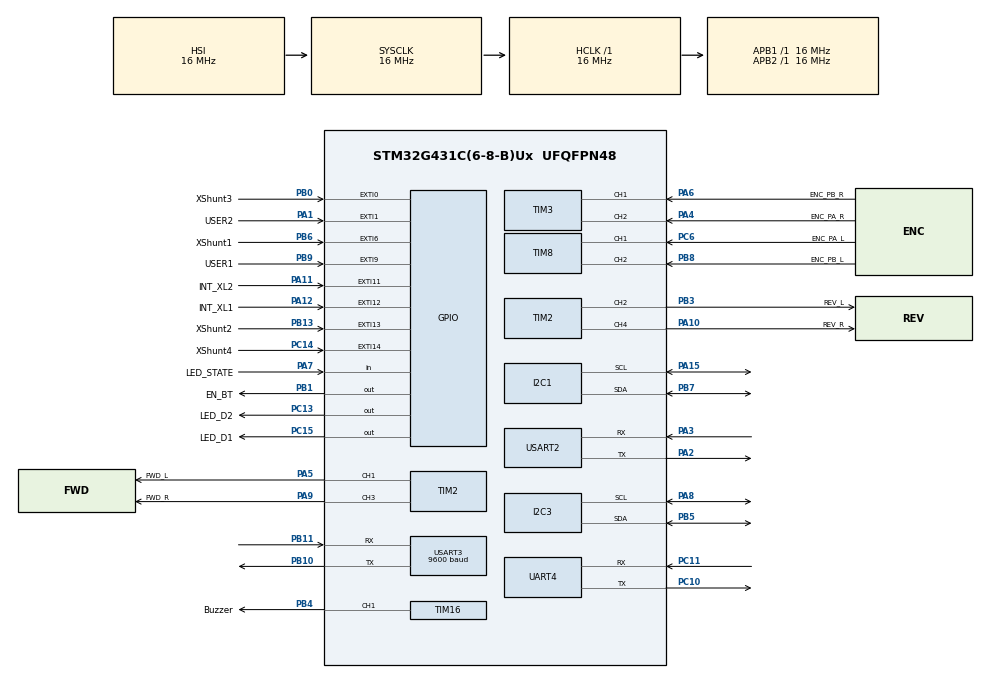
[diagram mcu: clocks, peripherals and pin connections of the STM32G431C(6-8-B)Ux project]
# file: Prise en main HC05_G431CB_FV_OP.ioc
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Dma.Request0=USART3_TX
Dma.USART3_TX.0.Direction=DMA_MEMORY_TO_PERIPH
Dma.USART3_TX.0.EventEnable=DISABLE
Dma.USART3_TX.0.Instance=DMA1_Channel1
Dma.USART3_TX.0.MemDataAlignment=DMA_MDATAALIGN_BYTE
Dma.USART3_TX.0.MemInc=DMA_MINC_ENABLE
Dma.USART3_TX.0.Mode=DMA_NORMAL
Dma.USART3_TX.0.PeriphDataAlignment=DMA_PDATAALIGN_BYTE
Dma.USART3_TX.0.PeriphInc=DMA_PINC_DISABLE
Dma.USART3_TX.0.Polarity=HAL_DMAMUX_REQ_GEN_RISING
Dma.USART3_TX.0.Priority=DMA_PRIORITY_LOW
Dma.USART3_TX.0.RequestNumber=1
Dma.USART3_TX.0.SignalID=NONE
Dma.USART3_TX.0.SyncEnable=DISABLE
Dma.USART3_TX.0.SyncPolarity=HAL_DMAMUX_SYNC_NO_EVENT
Dma.USART3_TX.0.SyncRequestNumber=1
Dma.USART3_TX.0.SyncSignalID=NONE
FREERTOS.Tasks01=defaultTask,0,128,StartDefaultTask,Default,NULL,Dynamic,NULL,NULL
I2C1.Timing=0x00503D58
I2C3.Timing=0x00503D58
Mcu.Family=STM32G4
Mcu.Name=STM32G431C(6-8-B)Ux
Mcu.Package=UFQFPN48
NVIC.DMA1_Channel1_IRQn=true\:5\:0\:false\:false\:true\:true\:false\:true\:true
NVIC.PriorityGroup=NVIC_PRIORITYGROUP_4
NVIC.TIM6_DAC_IRQn=true\:15\:0\:false\:false\:true\:false\:false\:true\:true
NVIC.TimeBase=TIM6_DAC_IRQn
NVIC.TimeBaseIP=TIM6
NVIC.USART3_IRQn=true\:5\:0\:false\:false\:true\:true\:true\:true\:true
PA1.GPIO_Label=USER2
PA1.Signal=GPXTI1
PA10.GPIO_Label=REV_R
PA10.Signal=S_TIM2_CH4
PA11.GPIO_Label=INT_XL2
PA11.Signal=GPXTI11
PA12.GPIO_Label=INT_XL1
PA12.Signal=GPXTI12
PA13.Mode=Serial_Wire
PA13.Signal=SYS_JTMS-SWDIO
PA14.Mode=Serial_Wire
PA14.Signal=SYS_JTCK-SWCLK
PA15.Mode=I2C
PA15.Signal=I2C1_SCL
PA2.Mode=Asynchronous
PA2.Signal=USART2_TX
PA3.Mode=Asynchronous
PA3.Signal=USART2_RX
PA4.GPIO_Label=ENC_PA_R
PA4.Signal=S_TIM3_CH2
PA5.GPIO_Label=FWD_L
PA5.Signal=S_TIM2_CH1
PA6.GPIO_Label=ENC_PB_R
PA6.Signal=S_TIM3_CH1
PA7.GPIO_Label=LED_STATE
PA7.Signal=GPIO_Input
PA8.Mode=I2C
PA8.Signal=I2C3_SCL
PA9.GPIO_Label=FWD_R
PA9.Signal=S_TIM2_CH3
PB0.GPIO_Label=XShunt3
PB0.Signal=GPXTI0
PB1.GPIO_Label=EN_BT
PB1.Signal=GPIO_Output
PB10.Mode=Asynchronous
PB10.Signal=USART3_TX
PB11.Mode=Asynchronous
PB11.Signal=USART3_RX
PB13.GPIO_Label=XShunt2
PB13.Signal=GPXTI13
PB15.GPIO_Label=M_CTRL
PB15.Signal=S_TIM15_CH2
PB3.GPIO_Label=REV_L
PB3.Signal=S_TIM2_CH2
PB4.GPIO_Label=Buzzer
PB4.Signal=S_TIM16_CH1
PB5.Mode=I2C
PB5.Signal=I2C3_SDA
PB6.GPIO_Label=XShunt1
PB6.Signal=GPXTI6
PB7.Mode=I2C
PB7.Signal=I2C1_SDA
PB8-BOOT0.GPIO_Label=ENC_PB_L
PB8-BOOT0.Signal=S_TIM8_CH2
PB9.GPIO_Label=USER1
PB9.Signal=GPXTI9
PC10.Mode=Asynchronous
PC10.Signal=UART4_TX
PC11.Mode=Asynchronous
PC11.Signal=UART4_RX
PC13.GPIO_Label=LED_D2
PC13.Signal=GPIO_Output
PC14-OSC32_IN.GPIO_Label=XShunt4
PC14-OSC32_IN.Signal=GPXTI14
PC15-OSC32_OUT.GPIO_Label=LED_D1
PC15-OSC32_OUT.Signal=GPIO_Output
PC6.GPIO_Label=ENC_PA_L
PC6.Signal=S_TIM8_CH1
PF0-OSC_IN.Mode=HSE-External-Oscillator
PF0-OSC_IN.Signal=RCC_OSC_IN
PF1-OSC_OUT.Mode=HSE-External-Oscillator
PF1-OSC_OUT.Signal=RCC_OSC_OUT
ProjectManager.HeapSize=0x200
ProjectManager.StackSize=0x400
ProjectManager.TargetToolchain=STM32CubeIDE
RCC.AHBFreq_Value=16000000
RCC.APB1Freq_Value=16000000
RCC.APB1TimFreq_Value=16000000
RCC.APB2Freq_Value=16000000
RCC.APB2TimFreq_Value=16000000
RCC.CortexFreq_Value=16000000
RCC.EXTERNAL_CLOCK_VALUE=12288000
RCC.HCLKFreq_Value=16000000
RCC.HSE_VALUE=8000000
RCC.HSI48_VALUE=48000000
RCC.HSI_VALUE=16000000
RCC.LSE_VALUE=32768
RCC.SYSCLKFreq_VALUE=16000000
RCC.USBFreq_Value=64000000
RCC.VCOOutputFreq_Value=128000000
SH.S_TIM15_CH2.0=TIM15_CH2
SH.S_TIM16_CH1.0=TIM16_CH1,PWM Generation1 CH1
SH.S_TIM2_CH1.0=TIM2_CH1,PWM Generation1 CH1
SH.S_TIM2_CH2.0=TIM2_CH2,PWM Generation2 CH2
SH.S_TIM2_CH3.0=TIM2_CH3,PWM Generation3 CH3
SH.S_TIM2_CH4.0=TIM2_CH4,PWM Generation4 CH4
SH.S_TIM3_CH1.0=TIM3_CH1,Encoder_Interface
SH.S_TIM3_CH2.0=TIM3_CH2,Encoder_Interface
SH.S_TIM8_CH1.0=TIM8_CH1,Encoder_Interface
SH.S_TIM8_CH2.0=TIM8_CH2,Encoder_Interface
TIM16.Channel=TIM_CHANNEL_1
TIM2.Channel-PWM\ Generation1\ CH1=TIM_CHANNEL_1
TIM2.Channel-PWM\ Generation2\ CH2=TIM_CHANNEL_2
TIM2.Channel-PWM\ Generation3\ CH3=TIM_CHANNEL_3
TIM2.Channel-PWM\ Generation4\ CH4=TIM_CHANNEL_4
USART2.VirtualMode-Asynchronous=VM_ASYNC
USART3.BaudRate=9600
USART3.SwapParam=ADVFEATURE_SWAP_ENABLE
USART3.VirtualMode-Asynchronous=VM_ASYNC
VP_FREERTOS_VS_CMSIS_V1.Mode=CMSIS_V1
VP_SYS_VS_DBSignals.Mode=DisableDeadBatterySignals
VP_SYS_VS_tim6.Mode=TIM6
VP_TIM16_VS_ClockSourceINT.Mode=Enable_Timer
board=custom

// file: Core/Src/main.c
/* USER CODE BEGIN Header */
/**
 ******************************************************************************
 * @file           : main.c
 * @brief          : Main program body
 ******************************************************************************
 * @attention
 *
 * Copyright (c) 2025 STMicroelectronics.
 * All rights reserved.
 *
 * This software is licensed under terms that can be found in the LICENSE file
 * in the root directory of this software component.
 * If no LICENSE file comes with this software, it is provided AS-IS.
 *
 ******************************************************************************
 */
/* USER CODE END Header */
#include "main.h"
#include "cmsis_os.h"
#include "dma.h"
#include "i2c.h"
#include "tim.h"
#include "usart.h"
#include "gpio.h"

/* USER CODE BEGIN Includes */
#include "HC05.h"
/* USER CODE END Includes */

/* USER CODE BEGIN PV */
h_hc05_t h_hc05 =
{
		.huart = &huart3
};
/* USER CODE END PV */

void SystemClock_Config(void);
void MX_FREERTOS_Init(void);

/* USER CODE BEGIN 0 */
int __io_putchar(int chr)
{
	HAL_UART_Transmit(&huart2, (uint8_t*) &chr, 1, HAL_MAX_DELAY);
	return chr;
}
/* USER CODE END 0 */

int main(void)
{

	/* MCU Configuration--------------------------------------------------------*/

	/* Reset of all peripherals, Initializes the Flash interface and the Systick. */
	HAL_Init();

	/* Configure the system clock */
	SystemClock_Config();

	/* Initialize all configured peripherals */
	MX_GPIO_Init();
	MX_DMA_Init();
	MX_I2C1_Init();
	MX_I2C3_Init();
	MX_TIM2_Init();
	MX_TIM3_Init();
	MX_TIM8_Init();
	MX_UART4_Init();
	MX_USART2_UART_Init();
	MX_USART3_UART_Init();
	MX_TIM16_Init();
	/* USER CODE BEGIN 2 */

	//INITS
	// PAS D'INIT POUR LE HC05...

	//CREATION DES TASKS
	HC05_Tasks_Create(&h_hc05);

	//LANCE LE SCHEDULER
	vTaskStartScheduler();

	/* USER CODE END 2 */

	/* Call init function for freertos objects (in cmsis_os2.c) */
	MX_FREERTOS_Init();

	/* Start scheduler */
	osKernelStart();

	/* We should never get here as control is now taken by the scheduler */

	/* Infinite loop */
	while (1)
	{

	}
}

void SystemClock_Config(void)
{
	RCC_OscInitTypeDef RCC_OscInitStruct = {0};
	RCC_ClkInitTypeDef RCC_ClkInitStruct = {0};

	/** Configure the main internal regulator output voltage
	 */
	HAL_PWREx_ControlVoltageScaling(PWR_REGULATOR_VOLTAGE_SCALE1);

	/** Initializes the RCC Oscillators according to the specified parameters
	 * in the RCC_OscInitTypeDef structure.
	 */
	RCC_OscInitStruct.OscillatorType = RCC_OSCILLATORTYPE_HSI;
	RCC_OscInitStruct.HSIState = RCC_HSI_ON;
	RCC_OscInitStruct.HSICalibrationValue = RCC_HSICALIBRATION_DEFAULT;
	RCC_OscInitStruct.PLL.PLLState = RCC_PLL_NONE;
	if (HAL_RCC_OscConfig(&RCC_OscInitStruct) != HAL_OK)
	{
		Error_Handler();
	}

	/** Initializes the CPU, AHB and APB buses clocks
	 */
	RCC_ClkInitStruct.ClockType = RCC_CLOCKTYPE_HCLK|RCC_CLOCKTYPE_SYSCLK
			|RCC_CLOCKTYPE_PCLK1|RCC_CLOCKTYPE_PCLK2;
	RCC_ClkInitStruct.SYSCLKSource = RCC_SYSCLKSOURCE_HSI;
	RCC_ClkInitStruct.AHBCLKDivider = RCC_SYSCLK_DIV1;
	RCC_ClkInitStruct.APB1CLKDivider = RCC_HCLK_DIV1;
	RCC_ClkInitStruct.APB2CLKDivider = RCC_HCLK_DIV1;

	if (HAL_RCC_ClockConfig(&RCC_ClkInitStruct, FLASH_LATENCY_0) != HAL_OK)
	{
		Error_Handler();
	}
}

/* USER CODE BEGIN 4 */
void HAL_UART_RxCpltCallback(UART_HandleTypeDef *huart)
{
	if (huart->Instance==USART3)
	{
		hc05_RX_callback(&h_hc05);
	}
}
/* USER CODE END 4 */

void HAL_TIM_PeriodElapsedCallback(TIM_HandleTypeDef *htim)
{
	if (htim->Instance == TIM6)
	{
		HAL_IncTick();
	}
}

void Error_Handler(void)
{
	__disable_irq();
	while (1)
	{
	}
}
